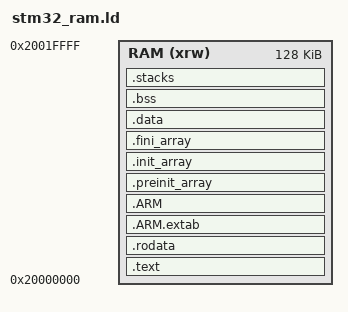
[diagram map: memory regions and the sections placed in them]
ENTRY(test_main);

_estack = ORIGIN(RAM) + LENGTH(RAM);

MEMORY {
  RAM (xrw) : ORIGIN = 0x20000000,  LENGTH = 128K
}

SECTIONS {
  .text : {
    . = ALIGN(4);

    *(.text)
    *(.text*)
    *(.glue_7)
    *(.glue_7t)
    *(.eh_frame)

    KEEP (*(.init))
    KEEP (*(.fini))

    . = ALIGN(4);
    _etext = .;
  } >RAM

  .rodata :
  {
    . = ALIGN(4);
    *(.rodata)
    *(.rodata*)
    . = ALIGN(4);
  } >RAM

  .ARM.extab   : {
    . = ALIGN(4);
    *(.ARM.extab* .gnu.linkonce.armextab.*)
    . = ALIGN(4);
  } >RAM

  .ARM : {
    . = ALIGN(4);
    __exidx_start = .;
    *(.ARM.exidx*)
    __exidx_end = .;
    . = ALIGN(4);
  } >RAM

  .preinit_array : {
    . = ALIGN(4);
    PROVIDE_HIDDEN (__preinit_array_start = .);
    KEEP (*(.preinit_array*))
    PROVIDE_HIDDEN (__preinit_array_end = .);
    . = ALIGN(4);
  } >RAM

  .init_array : {
    . = ALIGN(4);
    PROVIDE_HIDDEN (__init_array_start = .);
    KEEP (*(SORT(.init_array.*)))
    KEEP (*(.init_array*))
    PROVIDE_HIDDEN (__init_array_end = .);
    . = ALIGN(4);
  } >RAM

  .fini_array : {
    . = ALIGN(4);
    PROVIDE_HIDDEN (__fini_array_start = .);
    KEEP (*(SORT(.fini_array.*)))
    KEEP (*(.fini_array*))
    PROVIDE_HIDDEN (__fini_array_end = .);
    . = ALIGN(4);
  } >RAM

  _sidata = LOADADDR(.data);

  .data : {
    . = ALIGN(4);
    *(.data)
    *(.data*)

    . = ALIGN(4);
    _edata = .;

  } >RAM

  . = ALIGN(4);

  .bss : {
    _sbss = .;
    __bss_start__ = _sbss;

    *(.bss)
    *(.bss*)
    *(COMMON)

    . = ALIGN(4);
    _ebss = .;
    __bss_end__ = _ebss;
  } >RAM

  .stacks : {
    . = ALIGN(4);
    *(stacks)
    . = ALIGN(4);
  } >RAM

  /DISCARD/ :
  {
    libc.a ( * )
    libm.a ( * )
    libgcc.a ( * )
  }

  .ARM.attributes 0 : { *(.ARM.attributes) }
}
